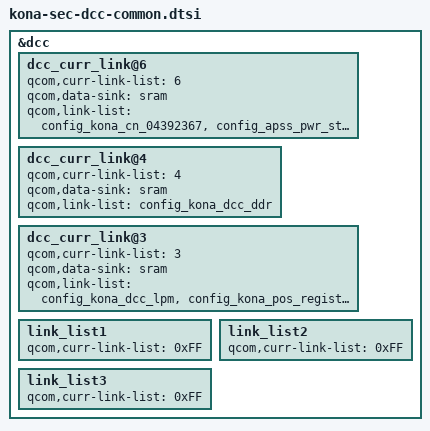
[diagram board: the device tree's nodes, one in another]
/* Copyright (c) 2020, The Linux Foundation. All rights reserved.
 *
 * This program is free software; you can redistribute it and/or modify
 * it under the terms of the GNU General Public License version 2 and
 * only version 2 as published by the Free Software Foundation.
 *
 * This program is distributed in the hope that it will be useful,
 * but WITHOUT ANY WARRANTY; without even the implied warranty of
 * MERCHANTABILITY or FITNESS FOR A PARTICULAR PURPOSE.  See the
 * GNU General Public License for more details.
 */

#include <dt-bindings/soc/qcom,dcc_v2.h>


/* config_kona_pos_register() */
#define config_kona_pos_register	\
	\
		/*  bail out if ftrace events aren't present */	\
		<DCC_READ 0x9102010 1 0>,	\
		<DCC_READ 0x9102410 1 0>,	\
		<DCC_READ 0x9142010 1 0>,	\
		<DCC_READ 0x9142410 1 0>,	\
		<DCC_READ 0x9102810 1 0>,	\
		<DCC_READ 0x9102C10 1 0>,	\
		<DCC_READ 0x9142810 1 0>,	\
		<DCC_READ 0x9142C10 1 0>,	\
		<DCC_READ 0x9110010 1 0>,	\
		<DCC_READ 0x9110410 1 0>,	\
		<DCC_READ 0x9150010 1 0>,	\
		<DCC_READ 0x9150410 1 0>,	\
		<DCC_READ 0x9100008 1 0>,	\
		<DCC_READ 0x910000C 1 0>,	\
		<DCC_READ 0x9100408 1 0>,	\
		<DCC_READ 0x910040C 1 0>,	\
		<DCC_READ 0x9140008 1 0>,	\
		<DCC_READ 0x914000C 1 0>,	\
		<DCC_READ 0x9140408 1 0>,	\
		<DCC_READ 0x914040C 1 0>,	\
		<DCC_READ 0x9180008 1 0>,	\
		<DCC_READ 0x918000C 1 0>,	\
		<DCC_READ 0x9180408 1 0>,	\
		<DCC_READ 0x918040C 1 0>,	\
		<DCC_READ 0x9100810 1 0>,	\
		<DCC_READ 0x9100C10 1 0>,	\
		<DCC_READ 0x9140810 1 0>,	\
		<DCC_READ 0x9140C10 1 0>,	\
		<DCC_READ 0x9100820 1 0>,	\
		<DCC_READ 0x9100C20 1 0>,	\
		<DCC_READ 0x9140820 1 0>,	\
		<DCC_READ 0x9140C20 1 0>,	\
		<DCC_READ 0x9100828 1 0>,	\
		<DCC_READ 0x910082C 1 0>,	\
		<DCC_READ 0x9100C28 1 0>,	\
		<DCC_READ 0x9100C2C 1 0>,	\
		<DCC_READ 0x9140828 1 0>,	\
		<DCC_READ 0x914082C 1 0>,	\
		<DCC_READ 0x9140C28 1 0>,	\
		<DCC_READ 0x9140C2C 1 0>

/* config_kona_dcc_ddr() */
#define config_kona_dcc_ddr	\
	\
		/* DDRSS */	\
		<DCC_READ 0x9050078 1 0>,	\
		<DCC_READ 0x9050110 8 0>,	\
		<DCC_READ 0x9080058 2 0>,	\
		<DCC_READ 0x90800C8 1 0>,	\
		<DCC_READ 0x90800D4 1 0>,	\
		<DCC_READ 0x90800E0 1 0>,	\
		<DCC_READ 0x90800EC 1 0>,	\
		<DCC_READ 0x90800F8 1 0>,	\
		<DCC_READ 0x908401C 1 0>,	\
		<DCC_READ 0x908403C 1 0>,	\
		<DCC_READ 0x908404C 2 0>,	\
		<DCC_READ 0x90840D4 1 0>,	\
		<DCC_READ 0x9084204 1 0>,	\
		<DCC_READ 0x908420C 1 0>,	\
		<DCC_READ 0x9084250 2 0>,	\
		<DCC_READ 0x9084260 3 0>,	\
		<DCC_READ 0x9084280 1 0>,	\
		<DCC_READ 0x90BA280 1 0>,	\
		<DCC_READ 0x90BA288 7 0>,	\
		<DCC_READ 0x9258610 4 0>,	\
		<DCC_READ 0x92D8610 4 0>,	\
		<DCC_READ 0x9358610 4 0>,	\
		<DCC_READ 0x93D8610 4 0>,	\
	\
		/*  LLCC */	\
		<DCC_READ 0x9220344 8 0>,	\
		<DCC_READ 0x9220370 6 0>,	\
		<DCC_READ 0x9220480 1 0>,	\
		<DCC_READ 0x9222400 1 0>,	\
		<DCC_READ 0x9222408 1 0>,	\
		<DCC_READ 0x922240C 1 0>,	\
		<DCC_READ 0x9223214 2 0>,	\
		<DCC_READ 0x9223220 3 0>,	\
		<DCC_READ 0x9223308 1 0>,	\
		<DCC_READ 0x9223318 1 0>,	\
		<DCC_READ 0x9232100 1 0>,	\
		<DCC_READ 0x9236040 6 0>,	\
		<DCC_READ 0x92360B0 1 0>,	\
		<DCC_READ 0x923E030 2 0>,	\
		<DCC_READ 0x9241000 1 0>,	\
		<DCC_READ 0x9242028 1 0>,	\
		<DCC_READ 0x9242044 3 0>,	\
		<DCC_READ 0x9242070 1 0>,	\
		<DCC_READ 0x9248030 1 0>,	\
		<DCC_READ 0x9248048 8 0>,	\
		<DCC_READ 0x92A0344 8 0>,	\
		<DCC_READ 0x92A0370 6 0>,	\
		<DCC_READ 0x92A0480 1 0>,	\
		<DCC_READ 0x92A2400 1 0>,	\
		<DCC_READ 0x92A2408 1 0>,	\
		<DCC_READ 0x92A240C 1 0>,	\
		<DCC_READ 0x92A3214 2 0>,	\
		<DCC_READ 0x92A3220 3 0>,	\
		<DCC_READ 0x92A3308 1 0>,	\
		<DCC_READ 0x92A3318 1 0>,	\
		<DCC_READ 0x92B2100 1 0>,	\
		<DCC_READ 0x92B6040 6 0>,	\
		<DCC_READ 0x92B60B0 1 0>,	\
		<DCC_READ 0x92BE030 2 0>,	\
		<DCC_READ 0x92C1000 1 0>,	\
		<DCC_READ 0x92C2028 1 0>,	\
		<DCC_READ 0x92C2044 3 0>,	\
		<DCC_READ 0x92C2070 1 0>,	\
		<DCC_READ 0x92C8030 1 0>,	\
		<DCC_READ 0x92C8048 8 0>,	\
		<DCC_READ 0x9320344 8 0>,	\
		<DCC_READ 0x9320370 6 0>,	\
		<DCC_READ 0x9320480 1 0>,	\
		<DCC_READ 0x9322400 1 0>,	\
		<DCC_READ 0x9322408 1 0>,	\
		<DCC_READ 0x932240C 1 0>,	\
		<DCC_READ 0x9323214 2 0>,	\
		<DCC_READ 0x9323220 3 0>,	\
		<DCC_READ 0x9323308 1 0>,	\
		<DCC_READ 0x9323318 1 0>,	\
		<DCC_READ 0x9332100 1 0>,	\
		<DCC_READ 0x9336040 6 0>,	\
		<DCC_READ 0x93360B0 1 0>,	\
		<DCC_READ 0x933E030 2 0>,	\
		<DCC_READ 0x9341000 1 0>,	\
		<DCC_READ 0x9342028 1 0>,	\
		<DCC_READ 0x9342044 3 0>,	\
		<DCC_READ 0x9342070 1 0>,	\
		<DCC_READ 0x9348030 1 0>,	\
		<DCC_READ 0x9348048 8 0>,	\
		<DCC_READ 0x93A0344 8 0>,	\
		<DCC_READ 0x93A0370 6 0>,	\
		<DCC_READ 0x93A0480 1 0>,	\
		<DCC_READ 0x93A2400 1 0>,	\
		<DCC_READ 0x93A2408 1 0>,	\
		<DCC_READ 0x93A240C 1 0>,	\
		<DCC_READ 0x93A3214 2 0>,	\
		<DCC_READ 0x93A3220 3 0>,	\
		<DCC_READ 0x93A3308 1 0>,	\
		<DCC_READ 0x93A3318 1 0>,	\
		<DCC_READ 0x93B2100 1 0>,	\
		<DCC_READ 0x93B6040 6 0>,	\
		<DCC_READ 0x93B60B0 1 0>,	\
		<DCC_READ 0x93BE030 2 0>,	\
		<DCC_READ 0x93C1000 1 0>,	\
		<DCC_READ 0x93C2028 1 0>,	\
		<DCC_READ 0x93C2044 3 0>,	\
		<DCC_READ 0x93C2070 1 0>,	\
		<DCC_READ 0x93C8030 1 0>,	\
		<DCC_READ 0x93C8048 8 0>,	\
		<DCC_READ 0x9622304 1 0>,	\
	\
		/*  MC5 */	\
		<DCC_READ 0x9270080 1 0>,	\
		<DCC_READ 0x9270310 1 0>,	\
		<DCC_READ 0x9270400 1 0>,	\
		<DCC_READ 0x9270410 6 0>,	\
		<DCC_READ 0x9270430 1 0>,	\
		<DCC_READ 0x9270440 1 0>,	\
		<DCC_READ 0x9270448 1 0>,	\
		<DCC_READ 0x92704A0 1 0>,	\
		<DCC_READ 0x92704B0 1 0>,	\
		<DCC_READ 0x92704B8 2 0>,	\
		<DCC_READ 0x92704D0 2 0>,	\
		<DCC_READ 0x9271400 1 0>,	\
		<DCC_READ 0x9273410 1 0>,	\
		<DCC_READ 0x92753B0 1 0>,	\
		<DCC_READ 0x9275804 1 0>,	\
		<DCC_READ 0x9275C1C 1 0>,	\
		<DCC_READ 0x9275C2C 1 0>,	\
		<DCC_READ 0x9275C38 1 0>,	\
		<DCC_READ 0x9276418 2 0>,	\
		<DCC_READ 0x9279100 1 0>,	\
		<DCC_READ 0x9279110 1 0>,	\
		<DCC_READ 0x9279120 1 0>,	\
		<DCC_READ 0x9279180 2 0>,	\
		<DCC_READ 0x92F0080 1 0>,	\
		<DCC_READ 0x92F0310 1 0>,	\
		<DCC_READ 0x92F0400 1 0>,	\
		<DCC_READ 0x92F0410 6 0>,	\
		<DCC_READ 0x92F0430 1 0>,	\
		<DCC_READ 0x92F0440 1 0>,	\
		<DCC_READ 0x92F0448 1 0>,	\
		<DCC_READ 0x92F04A0 1 0>,	\
		<DCC_READ 0x92F04B0 1 0>,	\
		<DCC_READ 0x92F04B8 2 0>,	\
		<DCC_READ 0x92F04D0 2 0>,	\
		<DCC_READ 0x92F1400 1 0>,	\
		<DCC_READ 0x92F3410 1 0>,	\
		<DCC_READ 0x92F53B0 1 0>,	\
		<DCC_READ 0x92F5804 1 0>,	\
		<DCC_READ 0x92F5C1C 1 0>,	\
		<DCC_READ 0x92F5C2C 1 0>,	\
		<DCC_READ 0x92F5C38 1 0>,	\
		<DCC_READ 0x92F6418 2 0>,	\
		<DCC_READ 0x92F9100 1 0>,	\
		<DCC_READ 0x92F9110 1 0>,	\
		<DCC_READ 0x92F9120 1 0>,	\
		<DCC_READ 0x92F9180 2 0>,	\
		<DCC_READ 0x9370080 1 0>,	\
		<DCC_READ 0x9370310 1 0>,	\
		<DCC_READ 0x9370400 1 0>,	\
		<DCC_READ 0x9370410 6 0>,	\
		<DCC_READ 0x9370430 1 0>,	\
		<DCC_READ 0x9370440 1 0>,	\
		<DCC_READ 0x9370448 1 0>,	\
		<DCC_READ 0x93704A0 1 0>,	\
		<DCC_READ 0x93704B0 1 0>,	\
		<DCC_READ 0x93704B8 2 0>,	\
		<DCC_READ 0x93704D0 2 0>,	\
		<DCC_READ 0x9371400 1 0>,	\
		<DCC_READ 0x9373410 1 0>,	\
		<DCC_READ 0x93753B0 1 0>,	\
		<DCC_READ 0x9375804 1 0>,	\
		<DCC_READ 0x9375C1C 1 0>,	\
		<DCC_READ 0x9375C2C 1 0>,	\
		<DCC_READ 0x9375C38 1 0>,	\
		<DCC_READ 0x9376418 2 0>,	\
		<DCC_READ 0x9379100 1 0>,	\
		<DCC_READ 0x9379110 1 0>,	\
		<DCC_READ 0x9379120 1 0>,	\
		<DCC_READ 0x9379180 2 0>,	\
		<DCC_READ 0x93F0080 1 0>,	\
		<DCC_READ 0x93F0310 1 0>,	\
		<DCC_READ 0x93F0400 1 0>,	\
		<DCC_READ 0x93F0410 6 0>,	\
		<DCC_READ 0x93F0430 1 0>,	\
		<DCC_READ 0x93F0440 1 0>,	\
		<DCC_READ 0x93F0448 1 0>,	\
		<DCC_READ 0x93F04A0 1 0>,	\
		<DCC_READ 0x93F04B0 1 0>,	\
		<DCC_READ 0x93F04B8 2 0>,	\
		<DCC_READ 0x93F04D0 2 0>,	\
		<DCC_READ 0x93F1400 1 0>,	\
		<DCC_READ 0x93F3410 1 0>,	\
		<DCC_READ 0x93F53B0 1 0>,	\
		<DCC_READ 0x93F5804 1 0>,	\
		<DCC_READ 0x93F5C1C 1 0>,	\
		<DCC_READ 0x93F5C2C 1 0>,	\
		<DCC_READ 0x93F5C38 1 0>,	\
		<DCC_READ 0x93F6418 2 0>,	\
		<DCC_READ 0x93F9100 1 0>,	\
		<DCC_READ 0x93F9110 1 0>,	\
		<DCC_READ 0x93F9120 1 0>,	\
		<DCC_READ 0x93F9180 2 0>,	\
	\
		/*  MC4 */	\
		<DCC_READ 0x9260080 1 0>,	\
		<DCC_READ 0x9260400 1 0>,	\
		<DCC_READ 0x9260410 3 0>,	\
		<DCC_READ 0x9260420 2 0>,	\
		<DCC_READ 0x9260430 1 0>,	\
		<DCC_READ 0x9260440 1 0>,	\
		<DCC_READ 0x9260448 1 0>,	\
		<DCC_READ 0x92604A0 1 0>,	\
		<DCC_READ 0x92604B0 1 0>,	\
		<DCC_READ 0x92604B8 2 0>,	\
		<DCC_READ 0x92604D0 2 0>,	\
		<DCC_READ 0x9261400 1 0>,	\
		<DCC_READ 0x9263410 1 0>,	\
		<DCC_READ 0x92653B0 1 0>,	\
		<DCC_READ 0x9265804 1 0>,	\
		<DCC_READ 0x9265B1C 1 0>,	\
		<DCC_READ 0x9265B2C 1 0>,	\
		<DCC_READ 0x9265B38 1 0>,	\
		<DCC_READ 0x9269100 1 0>,	\
		<DCC_READ 0x9269110 1 0>,	\
		<DCC_READ 0x9269120 1 0>,	\
		<DCC_READ 0x92E0080 1 0>,	\
		<DCC_READ 0x92E0400 1 0>,	\
		<DCC_READ 0x92E0410 3 0>,	\
		<DCC_READ 0x92E0420 2 0>,	\
		<DCC_READ 0x92E0430 1 0>,	\
		<DCC_READ 0x92E0440 1 0>,	\
		<DCC_READ 0x92E0448 1 0>,	\
		<DCC_READ 0x92E04A0 1 0>,	\
		<DCC_READ 0x92E04B0 1 0>,	\
		<DCC_READ 0x92E04B8 2 0>,	\
		<DCC_READ 0x92E04D0 2 0>,	\
		<DCC_READ 0x92E1400 1 0>,	\
		<DCC_READ 0x92E3410 1 0>,	\
		<DCC_READ 0x92E53B0 1 0>,	\
		<DCC_READ 0x92E5804 1 0>,	\
		<DCC_READ 0x92E5B1C 1 0>,	\
		<DCC_READ 0x92E5B2C 1 0>,	\
		<DCC_READ 0x92E5B38 1 0>,	\
		<DCC_READ 0x92E9100 1 0>,	\
		<DCC_READ 0x92E9110 1 0>,	\
		<DCC_READ 0x92E9120 1 0>,	\
		<DCC_READ 0x9360080 1 0>,	\
		<DCC_READ 0x9360400 1 0>,	\
		<DCC_READ 0x9360410 3 0>,	\
		<DCC_READ 0x9360420 2 0>,	\
		<DCC_READ 0x9360430 1 0>,	\
		<DCC_READ 0x9360440 1 0>,	\
		<DCC_READ 0x9360448 1 0>,	\
		<DCC_READ 0x93604A0 1 0>,	\
		<DCC_READ 0x93604B0 1 0>,	\
		<DCC_READ 0x93604B8 2 0>,	\
		<DCC_READ 0x93604D0 2 0>,	\
		<DCC_READ 0x9361400 1 0>,	\
		<DCC_READ 0x9363410 1 0>,	\
		<DCC_READ 0x93653B0 1 0>,	\
		<DCC_READ 0x9365804 1 0>,	\
		<DCC_READ 0x9365B1C 1 0>,	\
		<DCC_READ 0x9365B2C 1 0>,	\
		<DCC_READ 0x9365B38 1 0>,	\
		<DCC_READ 0x9369100 1 0>,	\
		<DCC_READ 0x9369110 1 0>,	\
		<DCC_READ 0x9369120 1 0>,	\
		<DCC_READ 0x93E0080 1 0>,	\
		<DCC_READ 0x93E0400 1 0>,	\
		<DCC_READ 0x93E0410 3 0>,	\
		<DCC_READ 0x93E0420 2 0>,	\
		<DCC_READ 0x93E0430 1 0>,	\
		<DCC_READ 0x93E0440 1 0>,	\
		<DCC_READ 0x93E0448 1 0>,	\
		<DCC_READ 0x93E04A0 1 0>,	\
		<DCC_READ 0x93E04B0 1 0>,	\
		<DCC_READ 0x93E04B8 2 0>,	\
		<DCC_READ 0x93E04D0 2 0>,	\
		<DCC_READ 0x93E1400 1 0>,	\
		<DCC_READ 0x93E3410 1 0>,	\
		<DCC_READ 0x93E53B0 1 0>,	\
		<DCC_READ 0x93E5804 1 0>,	\
		<DCC_READ 0x93E5B1C 1 0>,	\
		<DCC_READ 0x93E5B2C 1 0>,	\
		<DCC_READ 0x93E5B38 1 0>,	\
		<DCC_READ 0x93E9100 1 0>,	\
		<DCC_READ 0x93E9110 1 0>,	\
		<DCC_READ 0x93E9120 1 0>,	\
	\
		/*  DDRPHY */	\
		<DCC_READ 0x96B0868 1 0>,	\
		<DCC_READ 0x96B0870 1 0>,	\
		<DCC_READ 0x96B1004 1 0>,	\
		<DCC_READ 0x96B100C 1 0>,	\
		<DCC_READ 0x96B1014 1 0>,	\
		<DCC_READ 0x96B1204 1 0>,	\
		<DCC_READ 0x96B120C 1 0>,	\
		<DCC_READ 0x96B1214 1 0>,	\
		<DCC_READ 0x96B1504 1 0>,	\
		<DCC_READ 0x96B150C 1 0>,	\
		<DCC_READ 0x96B1514 1 0>,	\
		<DCC_READ 0x96B1604 1 0>,	\
		<DCC_READ 0x96B8100 1 0>,	\
		<DCC_READ 0x96B813C 1 0>,	\
		<DCC_READ 0x96B8500 1 0>,	\
		<DCC_READ 0x96B853C 1 0>,	\
		<DCC_READ 0x96B8A04 1 0>,	\
		<DCC_READ 0x96B8A18 1 0>,	\
		<DCC_READ 0x96B8EA8 1 0>,	\
		<DCC_READ 0x96B9044 1 0>,	\
		<DCC_READ 0x96B904C 1 0>,	\
		<DCC_READ 0x96B9054 1 0>,	\
		<DCC_READ 0x96B905C 1 0>,	\
		<DCC_READ 0x96B910C 2 0>,	\
		<DCC_READ 0x96B9204 1 0>,	\
		<DCC_READ 0x96B920C 1 0>,	\
		<DCC_READ 0x96B9238 1 0>,	\
		<DCC_READ 0x96B9240 1 0>,	\
		<DCC_READ 0x96B926C 1 0>,	\
		<DCC_READ 0x96B9394 1 0>,	\
		<DCC_READ 0x96B939C 1 0>,	\
		<DCC_READ 0x96B9704 1 0>,	\
		<DCC_READ 0x96B970C 1 0>,	\
		<DCC_READ 0x96F0868 1 0>,	\
		<DCC_READ 0x96F0870 1 0>,	\
		<DCC_READ 0x96F1004 1 0>,	\
		<DCC_READ 0x96F100C 1 0>,	\
		<DCC_READ 0x96F1014 1 0>,	\
		<DCC_READ 0x96F1204 1 0>,	\
		<DCC_READ 0x96F120C 1 0>,	\
		<DCC_READ 0x96F1214 1 0>,	\
		<DCC_READ 0x96F1504 1 0>,	\
		<DCC_READ 0x96F150C 1 0>,	\
		<DCC_READ 0x96F1514 1 0>,	\
		<DCC_READ 0x96F1604 1 0>,	\
		<DCC_READ 0x96F8100 1 0>,	\
		<DCC_READ 0x96F813C 1 0>,	\
		<DCC_READ 0x96F8500 1 0>,	\
		<DCC_READ 0x96F853C 1 0>,	\
		<DCC_READ 0x96F8A04 1 0>,	\
		<DCC_READ 0x96F8A18 1 0>,	\
		<DCC_READ 0x96F8EA8 1 0>,	\
		<DCC_READ 0x96F9044 1 0>,	\
		<DCC_READ 0x96F904C 1 0>,	\
		<DCC_READ 0x96F9054 1 0>,	\
		<DCC_READ 0x96F905C 1 0>,	\
		<DCC_READ 0x96F910C 2 0>,	\
		<DCC_READ 0x96F9204 1 0>,	\
		<DCC_READ 0x96F920C 1 0>,	\
		<DCC_READ 0x96F9238 1 0>,	\
		<DCC_READ 0x96F9240 1 0>,	\
		<DCC_READ 0x96F926C 1 0>,	\
		<DCC_READ 0x96F9394 1 0>,	\
		<DCC_READ 0x96F939C 1 0>,	\
		<DCC_READ 0x96F9704 1 0>,	\
		<DCC_READ 0x96F970C 1 0>,	\
		<DCC_READ 0x9730868 1 0>,	\
		<DCC_READ 0x9730870 1 0>,	\
		<DCC_READ 0x9731004 1 0>,	\
		<DCC_READ 0x973100C 1 0>,	\
		<DCC_READ 0x9731014 1 0>,	\
		<DCC_READ 0x9731204 1 0>,	\
		<DCC_READ 0x973120C 1 0>,	\
		<DCC_READ 0x9731214 1 0>,	\
		<DCC_READ 0x9731504 1 0>,	\
		<DCC_READ 0x973150C 1 0>,	\
		<DCC_READ 0x9731514 1 0>,	\
		<DCC_READ 0x9731604 1 0>,	\
		<DCC_READ 0x9738100 1 0>,	\
		<DCC_READ 0x973813C 1 0>,	\
		<DCC_READ 0x9738500 1 0>,	\
		<DCC_READ 0x973853C 1 0>,	\
		<DCC_READ 0x9738A04 1 0>,	\
		<DCC_READ 0x9738A18 1 0>,	\
		<DCC_READ 0x9738EA8 1 0>,	\
		<DCC_READ 0x9739044 1 0>,	\
		<DCC_READ 0x973904C 1 0>,	\
		<DCC_READ 0x9739054 1 0>,	\
		<DCC_READ 0x973905C 1 0>,	\
		<DCC_READ 0x973910C 2 0>,	\
		<DCC_READ 0x9739204 1 0>,	\
		<DCC_READ 0x973920C 1 0>,	\
		<DCC_READ 0x9739238 1 0>,	\
		<DCC_READ 0x9739240 1 0>,	\
		<DCC_READ 0x973926C 1 0>,	\
		<DCC_READ 0x9739394 1 0>,	\
		<DCC_READ 0x973939C 1 0>,	\
		<DCC_READ 0x9739704 1 0>,	\
		<DCC_READ 0x973970C 1 0>,	\
		<DCC_READ 0x9770868 1 0>,	\
		<DCC_READ 0x9770870 1 0>,	\
		<DCC_READ 0x9771004 1 0>,	\
		<DCC_READ 0x977100C 1 0>,	\
		<DCC_READ 0x9771014 1 0>,	\
		<DCC_READ 0x9771204 1 0>,	\
		<DCC_READ 0x977120C 1 0>,	\
		<DCC_READ 0x9771214 1 0>,	\
		<DCC_READ 0x9771504 1 0>,	\
		<DCC_READ 0x977150C 1 0>,	\
		<DCC_READ 0x9771514 1 0>,	\
		<DCC_READ 0x9771604 1 0>,	\
		<DCC_READ 0x9778100 1 0>,	\
		<DCC_READ 0x977813C 1 0>,	\
		<DCC_READ 0x9778500 1 0>,	\
		<DCC_READ 0x977853C 1 0>,	\
		<DCC_READ 0x9778A04 1 0>,	\
		<DCC_READ 0x9778A18 1 0>,	\
		<DCC_READ 0x9778EA8 1 0>,	\
		<DCC_READ 0x9779044 1 0>,	\
		<DCC_READ 0x977904C 1 0>,	\
		<DCC_READ 0x9779054 1 0>,	\
		<DCC_READ 0x977905C 1 0>,	\
		<DCC_READ 0x977910C 2 0>,	\
		<DCC_READ 0x9779204 1 0>,	\
		<DCC_READ 0x977920C 1 0>,	\
		<DCC_READ 0x9779238 1 0>,	\
		<DCC_READ 0x9779240 1 0>,	\
		<DCC_READ 0x977926C 1 0>,	\
		<DCC_READ 0x9779394 1 0>,	\
		<DCC_READ 0x977939C 1 0>,	\
		<DCC_READ 0x9779704 1 0>,	\
		<DCC_READ 0x977970C 1 0>,	\
	\
		/*  GEMNOC */	\
		<DCC_READ 0x910D100 3 0>,	\
		<DCC_READ 0x914D100 3 0>,	\
		<DCC_READ 0x918D100 4 0>,	\
		<DCC_READ 0x91A5100 1 0>,	\
		<DCC_READ 0x91AD100 1 0>,	\
		<DCC_READ 0x9100008 2 0>,	\
		<DCC_READ 0x9181220 8 0>,	\
		<DCC_READ 0x610110 5 0>,	\
	\
		/*  SHRM */	\
		<DCC_WRITE 0x06E0A00C 0x00600007 1>,	\
		<DCC_WRITE 0x06E0A01C 0x00136800 1>,	\
		<DCC_READ 0x06E0A014 1 1>,	\
		<DCC_WRITE 0x06E0A01C 0x00136810 1>,	\
		<DCC_READ 0x06E0A014 1 1>,	\
		<DCC_WRITE 0x06E0A01C 0x00136820 1>,	\
		<DCC_READ 0x06E0A014 1 1>,	\
		<DCC_WRITE 0x06E0A01C 0x00136830 1>,	\
		<DCC_READ 0x06E0A014 1 1>,	\
		<DCC_WRITE 0x06E0A01C 0x00136840 1>,	\
		<DCC_READ 0x06E0A014 1 1>,	\
		<DCC_WRITE 0x06E0A01C 0x00136850 1>,	\
		<DCC_READ 0x06E0A014 1 1>,	\
		<DCC_WRITE 0x06E0A01C 0x00136860 1>,	\
		<DCC_READ 0x06E0A014 1 1>,	\
		<DCC_WRITE 0x06E0A01C 0x00136870 1>,	\
		<DCC_READ 0x06E0A014 1 1>,	\
		<DCC_WRITE 0x06E0A01C 0x0003e9a0 1>,	\
		<DCC_WRITE 0x06E0A01C 0x001368a0 1>,	\
		<DCC_READ 0x06E0A014 1 1>,	\
		<DCC_WRITE 0x06E0A01C 0x0003c0a0 1>,	\
		<DCC_WRITE 0x06E0A01C 0x001368a0 1>,	\
		<DCC_READ 0x06E0A014 1 1>,	\
		<DCC_WRITE 0x06E0A01C 0x0003d1a0 1>,	\
		<DCC_WRITE 0x06E0A01C 0x001368a0 1>,	\
		<DCC_READ 0x06E0A014 1 1>,	\
		<DCC_WRITE 0x06E0A01C 0x0003d2a0 1>,	\
		<DCC_WRITE 0x06E0A01C 0x001368a0 1>,	\
		<DCC_READ 0x06E0A014 1 1>,	\
		<DCC_WRITE 0x06E0A01C 0x0003d5a0 1>,	\
		<DCC_WRITE 0x06E0A01C 0x001368a0 1>,	\
		<DCC_READ 0x06E0A014 1 1>,	\
		<DCC_WRITE 0x06E0A01C 0x0003d6a0 1>,	\
		<DCC_WRITE 0x06E0A01C 0x001368a0 1>,	\
		<DCC_READ 0x06E0A014 1 1>,	\
		<DCC_WRITE 0x06E0A01C 0x0003e8a0 1>,	\
		<DCC_WRITE 0x06E0A01C 0x001368a0 1>,	\
		<DCC_READ 0x06E0A014 1 1>,	\
		<DCC_WRITE 0x06E0A01C 0x0003eea0 1>,	\
		<DCC_WRITE 0x06E0A01C 0x001368a0 1>,	\
		<DCC_READ 0x06E0A014 1 1>,	\
		<DCC_WRITE 0x06E0A01C 0x0003b1a0 1>,	\
		<DCC_WRITE 0x06E0A01C 0x001368a0 1>,	\
		<DCC_READ 0x06E0A014 1 1>,	\
		<DCC_WRITE 0x06E0A01C 0x0003b2a0 1>,	\
		<DCC_WRITE 0x06E0A01C 0x001368a0 1>,	\
		<DCC_READ 0x06E0A014 1 1>,	\
		<DCC_WRITE 0x06E0A01C 0x0003b5a0 1>,	\
		<DCC_WRITE 0x06E0A01C 0x001368a0 1>,	\
		<DCC_READ 0x06E0A014 1 1>,	\
		<DCC_WRITE 0x06E0A01C 0x0003b6a0 1>,	\
		<DCC_WRITE 0x06E0A01C 0x001368a0 1>,	\
		<DCC_READ 0x06E0A014 1 1>,	\
		<DCC_WRITE 0x06E0A01C 0x0003c2a0 1>,	\
		<DCC_WRITE 0x06E0A01C 0x001368a0 1>,	\
		<DCC_READ 0x06E0A014 1 1>,	\
		<DCC_WRITE 0x06E0A01C 0x0003c5a0 1>,	\
		<DCC_WRITE 0x06E0A01C 0x001368a0 1>,	\
		<DCC_READ 0x06E0A014 1 1>,	\
		<DCC_WRITE 0x06E0A01C 0x0003c6a0 1>,	\
		<DCC_WRITE 0x06E0A01C 0x001368a0 1>,	\
		<DCC_READ 0x06E0A014 1 1>,	\
		<DCC_WRITE 0x06E0A014 0x0002000c 1>,	\
		<DCC_WRITE 0x06E0A01C 0x000368b0 1>,	\
		<DCC_WRITE 0x06E0A01C 0x00000ba8 1>,	\
		<DCC_WRITE 0x06E0A01C 0x0013B6A0 1>,	\
		<DCC_WRITE 0x06E0A01C 0x00F1E000 1>,	\
		<DCC_WRITE 0x06E0A008 0x00000007 1>,	\
		<DCC_READ 0x09067E00 124 0>

/* config_kona_dcc_gemnoc() */
#define config_kona_dcc_gemnoc	\
	\
		/* GemNOC for KONA start */	\
		<DCC_READ 0x091A9020 1 0>,	\
		<DCC_READ 0x09102008 1 0>,	\
		<DCC_READ 0x09142008 1 0>,	\
		<DCC_READ 0x09102408 1 0>,	\
		<DCC_READ 0x09142408 1 0>,	\
	\
		/* Dump Coherent even debug chain */	\
		<DCC_READ 0x09103808 1 0>,	\
		<DCC_LOOP 3 0 0>,	\
		<DCC_READ 0x09103810 1 0>,	\
		<DCC_READ 0x09103814 1 0>,	\
		<DCC_LOOP 1 0 0>,	\
	\
		/* Dump Non-Coherent Even Chain debug */	\
		<DCC_READ 0x09103888 1 0>,	\
		<DCC_LOOP 2 0 0>,	\
		<DCC_READ 0x09103890 1 0>,	\
		<DCC_READ 0x09103894 1 0>,	\
		<DCC_LOOP 1 0 0>,	\
	\
		/*  Dump Coherent Odd Chain debug */	\
		<DCC_READ 0x09143808 1 0>,	\
		<DCC_LOOP 3 0 0>,	\
		<DCC_READ 0x09143810 1 0>,	\
		<DCC_READ 0x09143814 1 0>,	\
		<DCC_LOOP 1 0 0>,	\
	\
		/* ; Dump Non-Coherent Odd Chain debug */	\
		<DCC_READ 0x09143888 1 0>,	\
		<DCC_LOOP 2 0 0>,	\
		<DCC_READ 0x09143890 1 0>,	\
		<DCC_READ 0x09143894 1 0>,	\
		<DCC_LOOP 1 0 0>,	\
	\
		/* ; Dump Coherent Sys Chain debug */	\
		<DCC_READ 0x09182808 1 0>,	\
		<DCC_LOOP 2 0 0>,	\
		<DCC_READ 0x09182810 1 0>,	\
		<DCC_READ 0x09182814 1 0>,	\
		<DCC_LOOP 1 0 0>,	\
	\
		/* ; Dump Non-Coherent Sys Chain debug */	\
		<DCC_READ 0x09182888 1 0>,	\
		<DCC_LOOP 3 0 0>,	\
		<DCC_READ 0x09182890 1 0>,	\
		<DCC_READ 0x09182894 1 0>,	\
		<DCC_LOOP 1 0 0>,	\
	\
		/* ; llcc0 pos debug Info dump */	\
		<DCC_READ 0x09103008 1 0>,	\
		<DCC_READ 0x0910300C 1 0>,	\
	\
		/* ; llcc0 pos Context Table Info dump - Retrieve context information */	\
		<DCC_WRITE 0x09103028 0x00000001 1>,	\
		<DCC_LOOP 0x41 0 0>,	\
		<DCC_READ 0x09103010 1 0>,	\
		<DCC_READ 0x09103014 1 0>,	\
		<DCC_LOOP 1 0 0>,	\
	\
		/* ; llcc2 pos debug info dump */	\
		<DCC_READ 0x09103408 1 0>,	\
		<DCC_READ 0x0910340C 1 0>,	\
	\
		/* ; llcc2 pos Context Table Info dump - Retrieve context information */	\
		<DCC_WRITE 0x09103428 0x00000001 1>,	\
		<DCC_LOOP 0x41 0 0>,	\
		<DCC_READ 0x09103410 1 0>,	\
		<DCC_READ 0x09103414 1 0>,	\
		<DCC_LOOP 1 0 0>,	\
	\
		/* ; llcc1 pos debug info dump */	\
		<DCC_READ 0x09143008 1 0>,	\
		<DCC_READ 0x0914300C 1 0>,	\
	\
		/* ; llcc1 pos Context Table Info dump - Retrieve context information */	\
		<DCC_WRITE 0x09143028 0x00000001 1>,	\
		<DCC_LOOP 0x41 0 0>,	\
		<DCC_READ 0x09143010 1 0>,	\
		<DCC_READ 0x09143014 1 0>,	\
		<DCC_LOOP 1 0 0>,	\
	\
		/* ; llcc3 pos debug info dump */	\
		<DCC_READ 0x09143408 1 0>,	\
		<DCC_READ 0x0914340C 1 0>,	\
	\
		/* ; llcc3 pos Context Table Info dump - Retrieve context information */	\
		<DCC_WRITE 0x09143428 0x00000001 1>,	\
		<DCC_LOOP 0x41 0 0>,	\
		<DCC_READ 0x09143410 1 0>,	\
		<DCC_READ 0x09143414 1 0>,	\
		<DCC_LOOP 1 0 0>,	\
	\
		/* ; PCIe pos debug info dump */	\
		<DCC_READ 0x09182008 1 0>,	\
		<DCC_READ 0x0918200C 1 0>,	\
	\
		/* ; PCIe pos Context Table Info dump - Retrieve context information */	\
		<DCC_WRITE 0x09182028 0x00000001 1>,	\
		<DCC_LOOP 0x11 0 0>,	\
		<DCC_READ 0x09182010 1 0>,	\
		<DCC_READ 0x09182014 1 0>,	\
		<DCC_LOOP 1 0 0>,	\
	\
		/* ; SNoC pos debug info dump */	\
		<DCC_READ 0x09182408 1 0>,	\
		<DCC_READ 0x0918240C 1 0>,	\
	\
		/* ; SNoC pos Context Table Info dump - Retrieve context information */	\
		<DCC_WRITE 0x09182428 0x00000001 1>,	\
		<DCC_LOOP 0x11 0 0>,	\
		<DCC_READ 0x09182410 1 0>,	\
		<DCC_READ 0x09182414 1 0>,	\
		<DCC_LOOP 1 0 0>,	\
	\
		/* CASE:04275452 */	\
		<DCC_READ 0x0B201020 2 0>

/* config_kona_dcc_gpu() */
#define config_kona_dcc_gpu	\
	\
		/* GCC */	\
		<DCC_READ 0x171004 1 0>,	\
		<DCC_READ 0x171154 1 0>,	\
		<DCC_READ 0x17100C 1 0>,	\
		<DCC_READ 0x171018 1 0>,	\
	\
		/* GPUCC */	\
		<DCC_READ 0x3D9106C 1 0>,	\
		<DCC_READ 0x3D9100C 1 0>,	\
		<DCC_READ 0x3D91010 1 0>,	\
		<DCC_READ 0x3D91014 1 0>,	\
		<DCC_READ 0x3D91070 1 0>,	\
		<DCC_READ 0x3D91074 1 0>,	\
		<DCC_READ 0x3D91098 1 0>,	\
		<DCC_READ 0x3D91004 1 0>,	\
		<DCC_READ 0x3D9109C 1 0>,	\
		<DCC_READ 0x3D91078 1 0>,	\
		<DCC_READ 0x3D91054 1 0>,	\
		<DCC_READ 0x03D9106C 1 0>,	\
		<DCC_READ 0x03D95004 1 0>,	\
		<DCC_READ 0x03D96004 1 0>,	\
		<DCC_READ 0x03D92004 1 0>,	\
		<DCC_READ 0x03D97004 1 0>,	\
		<DCC_READ 0x03D93004 1 0>,	\
		<DCC_READ 0x0017B03C 1 0>,	\
		<DCC_READ 0x0017C03C 1 0>,	\
		<DCC_READ 0x0017D03C 1 0>,	\
		<DCC_READ 0x0017E03C 1 0>,	\
		<DCC_READ 0x0011903C 1 0>,	\
		<DCC_READ 0x0018603C 1 0>,	\
		<DCC_READ 0x0018703C 1 0>,	\
		<DCC_READ 0x0017B064 1 0>,	\
		<DCC_READ 0x0017C064 1 0>,	\
		<DCC_READ 0x0017D064 1 0>,	\
		<DCC_READ 0x0017E064 1 0>,	\
		<DCC_READ 0x00119064 1 0>,	\
		<DCC_READ 0x00186064 1 0>,	\
		<DCC_READ 0x00187064 1 0>

/* config_kona_dcc_lpm_pcu() */
#define config_kona_dcc_lpm_pcu	\
	\
		/* PCU -DCC for LPM path */	\
		<DCC_READ 0x18000024 1 0>,	\
		<DCC_READ 0x18000040 4 0>,	\
		<DCC_READ 0x18010024 1 0>,	\
		<DCC_READ 0x18010040 4 0>,	\
		<DCC_READ 0x18020024 1 0>,	\
		<DCC_READ 0x18020040 4 0>,	\
		<DCC_READ 0x18030024 1 0>,	\
		<DCC_READ 0x18030040 4 0>,	\
		<DCC_READ 0x18040024 1 0>,	\
		<DCC_READ 0x18040040 4 0>,	\
		<DCC_READ 0x18050024 1 0>,	\
		<DCC_READ 0x18050040 4 0>,	\
		<DCC_READ 0x18060024 1 0>,	\
		<DCC_READ 0x18060040 4 0>,	\
		<DCC_READ 0x18070024 1 0>,	\
		<DCC_READ 0x18070040 4 0>,	\
		<DCC_READ 0x18080024 1 0>,	\
		<DCC_READ 0x18080040 3 0>,	\
		<DCC_READ 0x180800F8 1 0>,	\
		<DCC_READ 0x18080104 1 0>,	\
		<DCC_READ 0x1808011C 1 0>,	\
		<DCC_READ 0x18080128 1 0>

/* config_kona_dcc_lpm() */
#define config_kona_dcc_lpm	\
	\
		/* RSC -DCC for LPM path */	\
		<DCC_READ 0x18200400 1 0>,	\
		<DCC_READ 0x18200404 1 0>,	\
		<DCC_READ 0x18200408 1 0>,	\
		<DCC_READ 0x18200038 1 0>,	\
		<DCC_READ 0x18200040 1 0>,	\
		<DCC_READ 0x18200048 1 0>,	\
		<DCC_READ 0x18220038 1 0>,	\
		<DCC_READ 0x18220040 1 0>,	\
		<DCC_READ 0x182200D0 1 0>,	\
		<DCC_READ 0x18200030 1 0>,	\
		<DCC_READ 0x18200010 1 0>,	\
	\
		/* RSC -TCS for LPM path */	\
		<DCC_READ 0x1822000c 1 0>,	\
		<DCC_READ 0x18220d14 1 0>,	\
		<DCC_READ 0x18220fb4 1 0>,	\
		<DCC_READ 0x18221254 1 0>,	\
		<DCC_READ 0x182214f4 1 0>,	\
		<DCC_READ 0x18221794 1 0>,	\
		<DCC_READ 0x18221a34 1 0>,	\
		<DCC_READ 0x18221cd4 1 0>,	\
		<DCC_READ 0x18221f74 1 0>,	\
		<DCC_READ 0x18220d18 1 0>,	\
		<DCC_READ 0x18220fb8 1 0>,	\
		<DCC_READ 0x18221258 1 0>,	\
		<DCC_READ 0x182214f8 1 0>,	\
		<DCC_READ 0x18221798 1 0>,	\
		<DCC_READ 0x18221a38 1 0>,	\
		<DCC_READ 0x18221cd8 1 0>,	\
		<DCC_READ 0x18221f78 1 0>,	\
		<DCC_READ 0x18220d00 1 0>,	\
		<DCC_READ 0x18220d04 1 0>,	\
		<DCC_READ 0x18220d1c 1 0>,	\
		<DCC_READ 0x18220fbc 1 0>,	\
		<DCC_READ 0x1822125c 1 0>,	\
		<DCC_READ 0x182214fc 1 0>,	\
		<DCC_READ 0x1822179c 1 0>,	\
		<DCC_READ 0x18221a3c 1 0>,	\
		<DCC_READ 0x18221cdc 1 0>,	\
		<DCC_READ 0x18221f7c 1 0>,	\
		<DCC_READ 0x18221274 1 0>,	\
		<DCC_READ 0x18221288 1 0>,	\
		<DCC_READ 0x1822129c 1 0>,	\
		<DCC_READ 0x182212b0 1 0>,	\
		<DCC_READ 0x182212c4 1 0>,	\
		<DCC_READ 0x182212d8 1 0>,	\
		<DCC_READ 0x182212ec 1 0>,	\
		<DCC_READ 0x18221300 1 0>,	\
		<DCC_READ 0x18221314 1 0>,	\
		<DCC_READ 0x18221328 1 0>,	\
		<DCC_READ 0x1822133c 1 0>,	\
		<DCC_READ 0x18221350 1 0>,	\
		<DCC_READ 0x18221364 1 0>,	\
		<DCC_READ 0x18221378 1 0>,	\
		<DCC_READ 0x1822138c 1 0>,	\
		<DCC_READ 0x182213a0 1 0>,	\
		<DCC_READ 0x18221514 1 0>,	\
		<DCC_READ 0x18221528 1 0>,	\
		<DCC_READ 0x1822153c 1 0>,	\
		<DCC_READ 0x18221550 1 0>,	\
		<DCC_READ 0x18221564 1 0>,	\
		<DCC_READ 0x18221578 1 0>,	\
		<DCC_READ 0x1822158c 1 0>,	\
		<DCC_READ 0x182215a0 1 0>,	\
		<DCC_READ 0x182215b4 1 0>,	\
		<DCC_READ 0x182215c8 1 0>,	\
		<DCC_READ 0x182215dc 1 0>,	\
		<DCC_READ 0x182215f0 1 0>,	\
		<DCC_READ 0x18221604 1 0>,	\
		<DCC_READ 0x18221618 1 0>,	\
		<DCC_READ 0x1822162c 1 0>,	\
		<DCC_READ 0x18221640 1 0>,	\
		<DCC_READ 0x182217b4 1 0>,	\
		<DCC_READ 0x182217c8 1 0>,	\
		<DCC_READ 0x182217dc 1 0>,	\
		<DCC_READ 0x182217f0 1 0>,	\
		<DCC_READ 0x18221804 1 0>,	\
		<DCC_READ 0x18221818 1 0>,	\
		<DCC_READ 0x1822182c 1 0>,	\
		<DCC_READ 0x18221840 1 0>,	\
		<DCC_READ 0x18221854 1 0>,	\
		<DCC_READ 0x18221868 1 0>,	\
		<DCC_READ 0x1822187c 1 0>,	\
		<DCC_READ 0x18221890 1 0>,	\
		<DCC_READ 0x182218a4 1 0>,	\
		<DCC_READ 0x182218b8 1 0>,	\
		<DCC_READ 0x182218cc 1 0>,	\
		<DCC_READ 0x182218e0 1 0>,	\
		<DCC_READ 0x18221a54 1 0>,	\
		<DCC_READ 0x18221a68 1 0>,	\
		<DCC_READ 0x18221a7c 1 0>,	\
		<DCC_READ 0x18221a90 1 0>,	\
		<DCC_READ 0x18221aa4 1 0>,	\
		<DCC_READ 0x18221ab8 1 0>,	\
		<DCC_READ 0x18221acc 1 0>,	\
		<DCC_READ 0x18221ae0 1 0>,	\
		<DCC_READ 0x18221af4 1 0>,	\
		<DCC_READ 0x18221b08 1 0>,	\
		<DCC_READ 0x18221b1c 1 0>,	\
		<DCC_READ 0x18221b30 1 0>,	\
		<DCC_READ 0x18221b44 1 0>,	\
		<DCC_READ 0x18221b58 1 0>,	\
		<DCC_READ 0x18221b6c 1 0>,	\
		<DCC_READ 0x18221b80 1 0>,	\
		<DCC_READ 0x18221cf4 1 0>,	\
		<DCC_READ 0x18221d08 1 0>,	\
		<DCC_READ 0x18221d1c 1 0>,	\
		<DCC_READ 0x18221d30 1 0>,	\
		<DCC_READ 0x18221d44 1 0>,	\
		<DCC_READ 0x18221d58 1 0>,	\
		<DCC_READ 0x18221d6c 1 0>,	\
		<DCC_READ 0x18221d80 1 0>,	\
		<DCC_READ 0x18221d94 1 0>,	\
		<DCC_READ 0x18221da8 1 0>,	\
		<DCC_READ 0x18221dbc 1 0>,	\
		<DCC_READ 0x18221dd0 1 0>,	\
		<DCC_READ 0x18221de4 1 0>,	\
		<DCC_READ 0x18221df8 1 0>,	\
		<DCC_READ 0x18221e0c 1 0>,	\
		<DCC_READ 0x18221e20 1 0>,	\
		<DCC_READ 0x18221f94 1 0>,	\
		<DCC_READ 0x18221fa8 1 0>,	\
		<DCC_READ 0x18221fbc 1 0>,	\
		<DCC_READ 0x18221fd0 1 0>,	\
		<DCC_READ 0x18221fe4 1 0>,	\
		<DCC_READ 0x18221ff8 1 0>,	\
		<DCC_READ 0x1822200c 1 0>,	\
		<DCC_READ 0x18222020 1 0>,	\
		<DCC_READ 0x18222034 1 0>,	\
		<DCC_READ 0x18222048 1 0>,	\
		<DCC_READ 0x1822205c 1 0>,	\
		<DCC_READ 0x18222070 1 0>,	\
		<DCC_READ 0x18222084 1 0>,	\
		<DCC_READ 0x18222098 1 0>,	\
		<DCC_READ 0x182220ac 1 0>,	\
		<DCC_READ 0x182220c0 1 0>,	\
		<DCC_READ 0x18221278 1 0>,	\
		<DCC_READ 0x1822128c 1 0>,	\
		<DCC_READ 0x182212a0 1 0>,	\
		<DCC_READ 0x182212b4 1 0>,	\
		<DCC_READ 0x182212c8 1 0>,	\
		<DCC_READ 0x182212dc 1 0>,	\
		<DCC_READ 0x182212f0 1 0>,	\
		<DCC_READ 0x18221304 1 0>,	\
		<DCC_READ 0x18221318 1 0>,	\
		<DCC_READ 0x1822132c 1 0>,	\
		<DCC_READ 0x18221340 1 0>,	\
		<DCC_READ 0x18221354 1 0>,	\
		<DCC_READ 0x18221368 1 0>,	\
		<DCC_READ 0x1822137c 1 0>,	\
		<DCC_READ 0x18221390 1 0>,	\
		<DCC_READ 0x182213a4 1 0>,	\
		<DCC_READ 0x18221518 1 0>,	\
		<DCC_READ 0x1822152c 1 0>,	\
		<DCC_READ 0x18221540 1 0>,	\
		<DCC_READ 0x18221554 1 0>,	\
		<DCC_READ 0x18221568 1 0>,	\
		<DCC_READ 0x1822157c 1 0>,	\
		<DCC_READ 0x18221590 1 0>,	\
		<DCC_READ 0x182215a4 1 0>,	\
		<DCC_READ 0x182215b8 1 0>,	\
		<DCC_READ 0x182215cc 1 0>,	\
		<DCC_READ 0x182215e0 1 0>,	\
		<DCC_READ 0x182215f4 1 0>,	\
		<DCC_READ 0x18221608 1 0>,	\
		<DCC_READ 0x1822161c 1 0>,	\
		<DCC_READ 0x18221630 1 0>,	\
		<DCC_READ 0x18221644 1 0>,	\
		<DCC_READ 0x182217b8 1 0>,	\
		<DCC_READ 0x182217cc 1 0>,	\
		<DCC_READ 0x182217e0 1 0>,	\
		<DCC_READ 0x182217f4 1 0>,	\
		<DCC_READ 0x18221808 1 0>,	\
		<DCC_READ 0x1822181c 1 0>,	\
		<DCC_READ 0x18221830 1 0>,	\
		<DCC_READ 0x18221844 1 0>,	\
		<DCC_READ 0x18221858 1 0>,	\
		<DCC_READ 0x1822186c 1 0>,	\
		<DCC_READ 0x18221880 1 0>,	\
		<DCC_READ 0x18221894 1 0>,	\
		<DCC_READ 0x182218a8 1 0>,	\
		<DCC_READ 0x182218bc 1 0>,	\
		<DCC_READ 0x182218d0 1 0>,	\
		<DCC_READ 0x182218e4 1 0>,	\
		<DCC_READ 0x18221a58 1 0>,	\
		<DCC_READ 0x18221a6c 1 0>,	\
		<DCC_READ 0x18221a80 1 0>,	\
		<DCC_READ 0x18221a94 1 0>,	\
		<DCC_READ 0x18221aa8 1 0>,	\
		<DCC_READ 0x18221abc 1 0>,	\
		<DCC_READ 0x18221ad0 1 0>,	\
		<DCC_READ 0x18221ae4 1 0>,	\
		<DCC_READ 0x18221af8 1 0>,	\
		<DCC_READ 0x18221b0c 1 0>,	\
		<DCC_READ 0x18221b20 1 0>,	\
		<DCC_READ 0x18221b34 1 0>,	\
		<DCC_READ 0x18221b48 1 0>,	\
		<DCC_READ 0x18221b5c 1 0>,	\
		<DCC_READ 0x18221b70 1 0>,	\
		<DCC_READ 0x18221b84 1 0>,	\
		<DCC_READ 0x18221cf8 1 0>,	\
		<DCC_READ 0x18221d0c 1 0>,	\
		<DCC_READ 0x18221d20 1 0>,	\
		<DCC_READ 0x18221d34 1 0>,	\
		<DCC_READ 0x18221d48 1 0>,	\
		<DCC_READ 0x18221d5c 1 0>,	\
		<DCC_READ 0x18221d70 1 0>,	\
		<DCC_READ 0x18221d84 1 0>,	\
		<DCC_READ 0x18221d98 1 0>,	\
		<DCC_READ 0x18221dac 1 0>,	\
		<DCC_READ 0x18221dc0 1 0>,	\
		<DCC_READ 0x18221dd4 1 0>,	\
		<DCC_READ 0x18221de8 1 0>,	\
		<DCC_READ 0x18221dfc 1 0>,	\
		<DCC_READ 0x18221e10 1 0>,	\
		<DCC_READ 0x18221e24 1 0>,	\
		<DCC_READ 0x18221f98 1 0>,	\
		<DCC_READ 0x18221fac 1 0>,	\
		<DCC_READ 0x18221fc0 1 0>,	\
		<DCC_READ 0x18221fd4 1 0>,	\
		<DCC_READ 0x18221fe8 1 0>,	\
		<DCC_READ 0x18221ffc 1 0>,	\
		<DCC_READ 0x18222010 1 0>,	\
		<DCC_READ 0x18222024 1 0>,	\
		<DCC_READ 0x18222038 1 0>,	\
		<DCC_READ 0x1822204c 1 0>,	\
		<DCC_READ 0x18222060 1 0>,	\
		<DCC_READ 0x18222074 1 0>,	\
		<DCC_READ 0x18222088 1 0>,	\
		<DCC_READ 0x1822209c 1 0>,	\
		<DCC_READ 0x182220b0 1 0>,	\
		<DCC_READ 0x182220c4 1 0>

/* config_kona_dcc_core() */
#define config_kona_dcc_core	\
	\
		/*  core hang */	\
		<DCC_READ 0x1800005C 1 0>,	\
		<DCC_READ 0x1801005C 1 0>,	\
		<DCC_READ 0x1802005C 1 0>,	\
		<DCC_READ 0x1803005C 1 0>,	\
		<DCC_READ 0x1804005C 1 0>,	\
		<DCC_READ 0x1805005C 1 0>,	\
		<DCC_READ 0x1806005C 1 0>,	\
		<DCC_READ 0x1807005C 1 0>,	\
	\
		/* CPRh */	\
		<DCC_READ 0x18101908 1 0>,	\
		<DCC_READ 0x18101C18 1 0>,	\
		<DCC_READ 0x18390810 1 0>,	\
		<DCC_READ 0x18390C50 1 0>,	\
		<DCC_READ 0x18390814 1 0>,	\
		<DCC_READ 0x18390C54 1 0>,	\
		<DCC_READ 0x18390818 1 0>,	\
		<DCC_READ 0x18390C58 1 0>,	\
		<DCC_READ 0x18393A84 2 0>,	\
		<DCC_READ 0x18100908 1 0>,	\
		<DCC_READ 0x18100C18 1 0>,	\
		<DCC_READ 0x183A0810 1 0>,	\
		<DCC_READ 0x183A0C50 1 0>,	\
		<DCC_READ 0x183A0814 1 0>,	\
		<DCC_READ 0x183A0C54 1 0>,	\
		<DCC_READ 0x183A0818 1 0>,	\
		<DCC_READ 0x183A0C58 1 0>,	\
		<DCC_READ 0x183A3A84 2 0>,	\
		<DCC_READ 0x18393500 1 0>,	\
		<DCC_READ 0x18393580 1 0>,	\
		<DCC_READ 0x183A3500 1 0>,	\
		<DCC_READ 0x183A3580 1 0>,	\
	\
		/* Silver / L3 PLL */	\
		<DCC_READ 0x18280000 4 0>,	\
		<DCC_READ 0x18284000 4 0>,	\
	\
		/* Gold PLL */	\
		<DCC_READ 0x18282000 4 0>,	\
		<DCC_READ 0x18282028 1 0>,	\
		<DCC_READ 0x18282038 1 0>,	\
		<DCC_READ 0x18282080 5 0>,	\
		<DCC_READ 0x18286000 4 0>,	\
		<DCC_READ 0x18286028 1 0>,	\
		<DCC_READ 0x18286038 1 0>,	\
		<DCC_READ 0x18286080 5 0>,	\
	\
		/* rpmh */	\
		<DCC_READ 0x0C201244 1 0>,	\
		<DCC_READ 0x0C202244 1 0>,	\
		<DCC_READ 0x18300000 1 0>,	\
	\
		/* GOLD */	\
		<DCC_READ 0x1829208C 1 0>,	\
		<DCC_WRITE 0x1829209C 0x78 0>,	\
		<DCC_WRITE 0x1829209C 0x0 0>,	\
		<DCC_WRITE 0x18292048 0x1 0>,	\
		<DCC_WRITE 0x18292090 0x0 0>,	\
		<DCC_WRITE 0x18292090 0x25 0>,	\
		<DCC_READ 0x18292098 1 0>,	\
		<DCC_WRITE 0x18292048 0x1D 0>,	\
		<DCC_WRITE 0x18292090 0x0 0>,	\
		<DCC_WRITE 0x18292090 0x25 0>,	\
		<DCC_READ 0x18292098 1 0>,	\
	\
		/* GOLD+ */	\
		<DCC_READ 0x1829608C 1 0>,	\
		<DCC_WRITE 0x1829609C 0x78 0>,	\
		<DCC_WRITE 0x1829609C 0x0 0>,	\
		<DCC_WRITE 0x18296048 0x1 0>,	\
		<DCC_WRITE 0x18296090 0x0 0>,	\
		<DCC_WRITE 0x18296090 0x25 0>,	\
		<DCC_READ 0x18296098 1 0>,	\
		<DCC_WRITE 0x18296048 0x1D 0>,	\
		<DCC_WRITE 0x18296090 0x0 0>,	\
		<DCC_WRITE 0x18296090 0x25 0>,	\
		<DCC_READ 0x18296098 1 0>

/* config_kona_dcc_edu() */
#define config_kona_dcc_edu	\
		<DCC_READ 0x088E1014 1 0>,	\
		<DCC_READ 0x088E2000 1 0>

/* config_kona_dcc_tcs() */
#define config_kona_dcc_tcs	\
	\
		/* TCS */	\
		/* <DCC_READ 0x18220D14 3 0>, */	\
		/* <DCC_READ 0x18220D30 4 0>, */	\
		/* <DCC_READ 0x18220D44 4 0>, */	\
		/* <DCC_READ 0x18220D58 4 0>, */	\
		/* <DCC_READ 0x18220FB4 3 0>, */	\
		/* <DCC_READ 0x18220FD0 4 0>, */	\
		/* <DCC_READ 0x18220FE4 4 0>, */	\
		/* <DCC_READ 0x18220FF8 4 0>, */	\
		/* <DCC_READ 0x18220D04 1 0>, */	\
		/* <DCC_READ 0x18220D00 1 0> */

/* config_kona_dcc_sys_agnoc_error() */
#define config_kona_dcc_sys_agnoc_error	\
	\
		/* Agnoc Error syndrome start */	\
		<DCC_READ 0x16E0010 1 0>,	\
		<DCC_READ 0x16E0020 1 0>,	\
		<DCC_READ 0x16E0024 1 0>,	\
		<DCC_READ 0x16E0028 1 0>,	\
		<DCC_READ 0x16E002C 1 0>,	\
		<DCC_READ 0x16E0030 1 0>,	\
		<DCC_READ 0x16E0034 1 0>,	\
		<DCC_READ 0x16E0038 1 0>,	\
		<DCC_READ 0x16E003C 1 0>,	\
		<DCC_READ 0x16E0248 1 0>,	\
		/* <DCC_READ 0x1700010 1 0>, */	\
		/* <DCC_READ 0x1700020 1 0>, */	\
		/* <DCC_READ 0x1700024 1 0>, */	\
		/* <DCC_READ 0x1700028 1 0>, */	\
		/* <DCC_READ 0x170002C 1 0>, */	\
		/* <DCC_READ 0x1700030 1 0>, */	\
		/* <DCC_READ 0x1700034 1 0>, */	\
		/* <DCC_READ 0x1700038 1 0>, */	\
		/* <DCC_READ 0x170003C 1 0>, */	\
		/* <DCC_READ 0x1700448 1 0>, */	\
	\
		/* DCNOC Error Start */	\
		<DCC_READ 0x90C0010 1 0>,	\
		<DCC_READ 0x90C0020 1 0>,	\
		<DCC_READ 0x90C0024 1 0>,	\
		<DCC_READ 0x90C0028 1 0>,	\
		<DCC_READ 0x90C002C 1 0>,	\
		<DCC_READ 0x90C0030 1 0>,	\
		<DCC_READ 0x90C0034 1 0>,	\
		<DCC_READ 0x90C0038 1 0>,	\
		<DCC_READ 0x90C003C 1 0>,	\
		<DCC_READ 0x90C0248 1 0>,	\
	\
		/* MNOC Error Start */	\
		<DCC_READ 0x1740010 1 0>,	\
		<DCC_READ 0x1740020 1 0>,	\
		<DCC_READ 0x1740024 1 0>,	\
		<DCC_READ 0x1740028 1 0>,	\
		<DCC_READ 0x174002C 1 0>,	\
		<DCC_READ 0x1740030 1 0>,	\
		<DCC_READ 0x1740034 1 0>,	\
		<DCC_READ 0x1740038 1 0>,	\
		<DCC_READ 0x174003C 1 0>,	\
		<DCC_READ 0x1740248 1 0>,	\
	\
		/* CNOC Error Start */	\
		<DCC_READ 0x1500010 1 0>,	\
		<DCC_READ 0x1500020 1 0>,	\
		<DCC_READ 0x1500024 1 0>,	\
		<DCC_READ 0x1500028 1 0>,	\
		<DCC_READ 0x150002C 1 0>,	\
		<DCC_READ 0x1500030 1 0>,	\
		<DCC_READ 0x1500034 1 0>,	\
		<DCC_READ 0x1500038 1 0>,	\
		<DCC_READ 0x150003C 1 0>,	\
		<DCC_READ 0x1500248 1 0>,	\
		<DCC_READ 0x150024C 1 0>,	\
		<DCC_READ 0x1500448 1 0>,	\
	\
		/* sysNOC Error Start */	\
		<DCC_READ 0x1620010 1 0>,	\
		<DCC_READ 0x1620018 1 0>,	\
		<DCC_READ 0x1620020 1 0>,	\
		<DCC_READ 0x1620024 1 0>,	\
		<DCC_READ 0x1620028 1 0>,	\
		<DCC_READ 0x162002C 1 0>,	\
		<DCC_READ 0x1620030 1 0>,	\
		<DCC_READ 0x1620034 1 0>,	\
		<DCC_READ 0x1620038 1 0>,	\
		<DCC_READ 0x162003C 1 0>,	\
		<DCC_READ 0x1620248 1 0>

/* config_kona_dcc_sys_agnoc() */
#define config_kona_dcc_sys_agnoc	\
	\
		/* SYSNOC start */	\
		<DCC_READ 0x162C100 1 0>,	\
		<DCC_READ 0x162C104 1 0>,	\
		<DCC_READ 0x162C108 1 0>,	\
		<DCC_READ 0x162C10C 1 0>,	\
		<DCC_READ 0x162C300 1 0>,	\
		<DCC_READ 0x162C304 1 0>,	\
		<DCC_READ 0x162C308 1 0>,	\
		<DCC_READ 0x162C30C 1 0>,	\
		<DCC_READ 0x162C500 1 0>,	\
		<DCC_READ 0x162C504 1 0>,	\
		<DCC_READ 0x162C700 1 0>,	\
		<DCC_READ 0x162C900 1 0>,	\
	\
		/* AGNOC start */	\
		/* <DCC_READ 0x16E0300 1 0>, */	\
		/* <DCC_READ 0x16E0304 1 0>, */	\
		/* <DCC_READ 0x16E0308 1 0>, */	\
		/* <DCC_READ 0x16E030C 1 0>, */	\
		/* <DCC_READ 0x16E0310 1 0>, */	\
		/* <DCC_READ 0x16E0700 1 0>, */	\
		/* <DCC_READ 0x1700500 1 0>, */	\
		/* <DCC_READ 0x1700504 1 0>, */	\
		/* <DCC_READ 0x1700508 1 0>, */	\
		/* <DCC_READ 0x170050C 1 0>, */	\
		/* <DCC_READ 0x1700900 1 0>, */	\
		/* <DCC_READ 0x1700904 1 0>, */	\
		/* <DCC_READ 0x1700908 1 0>, */	\
		/* <DCC_READ 0x1700B00 1 0>, */	\
		/* <DCC_READ 0x1700B04 1 0>, */	\
	\
		/* cdspnoc start */	\
		/* <DCC_READ 0x1700D00 1 0>, */	\
		/* <DCC_READ 0x1700D04 1 0>, */	\
		/* <DCC_READ 0x1700D08 1 0>, */	\
		/* <DCC_READ 0x1700D0C 1 0>, */	\
	\
		/* DCNOC Start */	\
		<DCC_READ 0x90C4100 1 0>,	\
		<DCC_READ 0x90C4104 1 0>,	\
		<DCC_READ 0x90C4108 1 0>,	\
		<DCC_READ 0x90C410C 1 0>,	\
		<DCC_READ 0x90C4110 1 0>,	\
		<DCC_READ 0x90C4114 1 0>,	\
	\
		/* MNOC Start */	\
		<DCC_READ 0x1740300 1 0>,	\
		<DCC_READ 0x1740304 1 0>,	\
		<DCC_READ 0x1740308 1 0>,	\
		<DCC_READ 0x174030C 1 0>,	\
		<DCC_READ 0x1740310 1 0>,	\
		<DCC_READ 0x1740314 1 0>,	\
		<DCC_READ 0x1740318 1 0>,	\
		<DCC_READ 0x174031C 1 0>,	\
	\
		/* CNOC Start */	\
		<DCC_READ 0x1501100 1 0>,	\
		<DCC_READ 0x1501104 1 0>,	\
		<DCC_READ 0x1501108 1 0>,	\
		<DCC_READ 0x1501300 1 0>,	\
		<DCC_READ 0x1501500 1 0>,	\
		<DCC_READ 0x1501700 1 0>,	\
		<DCC_READ 0x1501704 1 0>,	\
		<DCC_READ 0x1501708 1 0>,	\
		<DCC_READ 0x1501900 1 0>,	\
		<DCC_READ 0x1501904 1 0>,	\
		<DCC_READ 0x1501908 1 0>,	\
		<DCC_READ 0x1501D00 1 0>,	\
		<DCC_READ 0x1501D04 1 0>,	\
		<DCC_READ 0x1501F00 1 0>,	\
		<DCC_READ 0x1501F04 1 0>

/* kona_dcc_async_package() */
#define kona_dcc_async_package	\
	\
		/*  Function to send ASYNC package in TPDA */	\
		<DCC_WRITE 0x06004FB0 0xc5acce55 0>,	\
		<DCC_WRITE 0x0600408c 0xff 0>,	\
		<DCC_WRITE 0x06004FB0 0x0 0>

/* config_kona_sysco_ack() */
#define config_kona_sysco_ack	\
		<DCC_READ 0x09084124 1 0>,	\
		<DCC_READ 0x09084130 1 0>,	\
		<DCC_READ 0x09084080 1 0>,	\
		<DCC_READ 0x09084068 2 0>,	\
		<DCC_READ 0x09084070 1 0>,	\
		<DCC_READ 0x09084084 1 0>,	\
		<DCC_READ 0x09084060 2 0>,	\
		<DCC_READ 0x09084058 2 0>,	\
		<DCC_READ 0x09084078 2 0>,	\
		<DCC_READ 0x0908415C 1 0>,	\
		<DCC_READ 0x09084150 1 0>

/* config_boot_misc() */
#define config_boot_misc	\
		<DCC_READ 0x01FD3000 1 0>

/* config_apss_pwr_state() */
#define config_apss_pwr_state	\
	\
		/* APSS_L3_PWR_GATE_STATUS */	\
		<DCC_WRITE 0x18080010 0x1 0>

/* clock_domain_status() */
#define clock_domain_status	\
	\
		/*  Case Number:  04300558 */	\
		<DCC_READ 0x1859001C 1 0>,	\
		<DCC_READ 0x18590020 1 0>,	\
		<DCC_READ 0x18590300 1 0>,	\
		<DCC_READ 0x1859034C 1 0>,	\
		<DCC_READ 0x185903BC 1 0>,	\
		<DCC_READ 0x185903C0 1 0>,	\
		<DCC_READ 0x185900E8 1 0>,	\
		<DCC_READ 0x185900DC 1 0>,	\
		<DCC_READ 0x1859101C 1 0>,	\
		<DCC_READ 0x18591020 1 0>,	\
		<DCC_READ 0x18591300 1 0>,	\
		<DCC_READ 0x1859134C 1 0>,	\
		<DCC_READ 0x185913BC 1 0>,	\
		<DCC_READ 0x185913C0 1 0>,	\
		<DCC_READ 0x185910E8 1 0>,	\
		<DCC_READ 0x185910DC 1 0>,	\
		<DCC_READ 0x1859201C 1 0>,	\
		<DCC_READ 0x18592020 1 0>,	\
		<DCC_READ 0x18592300 1 0>,	\
		<DCC_READ 0x1859234C 1 0>,	\
		<DCC_READ 0x185923BC 1 0>,	\
		<DCC_READ 0x185923C0 1 0>,	\
		<DCC_READ 0x185920E8 1 0>,	\
		<DCC_READ 0x185920DC 1 0>,	\
		<DCC_READ 0x1859301C 1 0>,	\
		<DCC_READ 0x18593020 1 0>,	\
		<DCC_READ 0x18593300 1 0>,	\
		<DCC_READ 0x1859334C 1 0>,	\
		<DCC_READ 0x185933BC 1 0>,	\
		<DCC_READ 0x185933C0 1 0>,	\
		<DCC_READ 0x185930E8 1 0>,	\
		<DCC_READ 0x185930DC 1 0>

/* config_kona_cn_04392367() */
#define config_kona_cn_04392367	\
		<DCC_WRITE 0x18080000 0x1 0>

/* config_kona_cn_04392643() */
#define config_kona_cn_04392643	\
	\
		/*  APSS_CL_GICCLK_QCHANNEL_FSM_STS */	\
		<DCC_READ 0x18080070 0x1 0>,	\
	\
		/*  DPCC_REG_DPCC_DCNOC_CFG_CBC */	\
		<DCC_READ 0x09084164 1 0>,	\
	\
		/*  DPCC_REG_DPCC_MC4_CFG_CBCR */	\
		<DCC_READ 0x90840C8 1 0>,	\
	\
		/*  DPCC_REG_DPCC_MC5_CFG_CBCR */	\
		<DCC_READ 0x9084110 1 0>,	\
	\
		/*  DPCC_REG_DPCC_SHUB_CFG_CBCR */	\
		<DCC_READ 0x9084078 1 0>
#define config_kona_dcc_testbus	\
	\
		/* config_kona_dcc_testbus */	\
		/* GFX_0_TBU */	\
		<DCC_WRITE 0x3dc2008 0x40 0>,	\
		<DCC_READ 0x3dc2008 1 0>,	\
		<DCC_READ 0x3dc5020 2 0>,	\
		<DCC_WRITE 0x3dc2008 0x80 0>,	\
		<DCC_READ 0x3dc2008 1 0>,	\
		<DCC_READ 0x3dc5020 2 0>,	\
		<DCC_WRITE 0x3dc2008 0x87 0>,	\
		<DCC_READ 0x3dc2008 1 0>,	\
		<DCC_READ 0x3dc5020 2 0>,	\
		<DCC_WRITE 0x3dc2008 0xaf 0>,	\
		<DCC_READ 0x3dc2008 1 0>,	\
		<DCC_READ 0x3dc5020 2 0>,	\
		<DCC_WRITE 0x3dc2008 0xc0 0>,	\
		<DCC_READ 0x3dc2008 1 0>,	\
		<DCC_READ 0x3dc5020 2 0>,	\
		/* GFX_1_TBU */	\
		<DCC_WRITE 0x3dc2008 0x40 0>,	\
		<DCC_READ 0x3dc2008 1 0>,	\
		<DCC_READ 0x3dc9020 2 0>,	\
		<DCC_WRITE 0x3dc2008 0x80 0>,	\
		<DCC_READ 0x3dc2008 1 0>,	\
		<DCC_READ 0x3dc9020 2 0>,	\
		<DCC_WRITE 0x3dc2008 0x87 0>,	\
		<DCC_READ 0x3dc2008 1 0>,	\
		<DCC_READ 0x3dc9020 2 0>,	\
		<DCC_WRITE 0x3dc2008 0xaf 0>,	\
		<DCC_READ 0x3dc2008 1 0>,	\
		<DCC_READ 0x3dc9020 2 0>,	\
		<DCC_WRITE 0x3dc2008 0xbc 0>,	\
		<DCC_READ 0x3dc2008 1 0>,	\
		<DCC_READ 0x3dc9020 2 0>,	\
		<DCC_WRITE 0x3dc2008 0xc0 0>,	\
		<DCC_READ 0x3dc2008 1 0>,	\
		<DCC_READ 0x3dc9020 2 0>
		
&dcc {
	dcc_curr_link@6 {
		qcom,curr-link-list = <6>;
		qcom,data-sink = "sram";
		qcom,link-list =
			config_kona_cn_04392367,
			config_apss_pwr_state,
			config_kona_dcc_core,
			config_kona_dcc_gemnoc,
			/* CN 04392367 disable config_kona_dcc_sys_agnoc */
			/* config_kona_dcc_sys_agnoc, */
			config_kona_dcc_gpu,
			config_kona_dcc_edu,
			config_kona_dcc_lpm_pcu,
			config_kona_dcc_ddr,
			config_kona_sysco_ack,
			config_boot_misc,
			clock_domain_status,
			config_kona_cn_04392643,
			config_kona_dcc_testbus;
	};

	dcc_curr_link@4 {
		qcom,curr-link-list = <4>;
		qcom,data-sink = "sram";
		qcom,link-list =
			config_kona_dcc_ddr;
	};

#if 0  /* disabled since FC1.1 */
	dcc_curr_link@7 {
		qcom,curr-link-list = <7>;
		qcom,data-sink = "sram";
		qcom,link-list =
			/* config_kona_dcc_ddr; */
	};
#endif

	dcc_curr_link@3 {
		qcom,curr-link-list = <3>;
		qcom,data-sink = "sram";
		qcom,link-list =
			/* kona_dcc_async_package, */
			config_kona_dcc_lpm,
			/* CN 04392367 disable config_kona_dcc_sys_agnoc_error */
			/* config_kona_dcc_sys_agnoc_error, */
			config_kona_pos_register;
	};

	/* TODO: invalidate link lists in kona.dtsi file */
	link_list1 {
		qcom,curr-link-list = <0xFF>;
	};

	link_list2 {
		qcom,curr-link-list = <0xFF>;
	};

	link_list3 {
		qcom,curr-link-list = <0xFF>;
	};
};
